# f28004x_periph_ac_regs register map
Vendor: Texas Instruments
Peripheral module from a debugger description file (folder C2000).
Address unit: 16 bits
Registers are 32-bit, read-write, no defined reset value unless marked. A register's access mark holds for its fields unless they carry their own. Offsets are as the file gives them; lines under a group give offsets from that group; [hi:lo] are bit positions; {n}, {i} and the like mark numbered series; 'fields as' and 'values as' point back to an identical list; <NAME> marks a mode.

## PERIPH_AC_REGS — PERIPH AC Registers
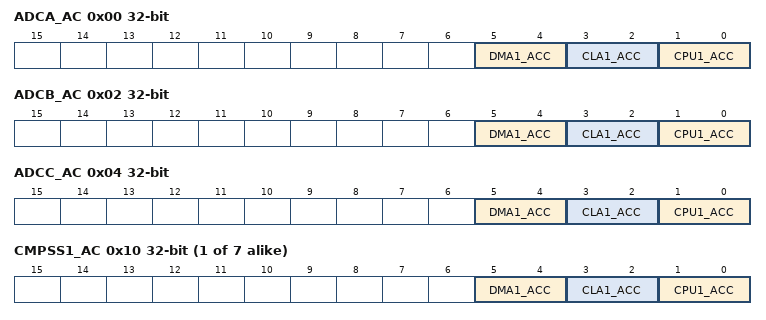
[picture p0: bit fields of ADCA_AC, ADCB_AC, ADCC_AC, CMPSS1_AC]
0x00 ADCA_AC — ADCA Master Access Control Register
  [5:4] DMA1_ACC — DMA1 Access Conditions to Peripheral
  [3:2] CLA1_ACC — CLA1 Access Conditions to Peripheral
  [1:0] CPU1_ACC — CPU1 Access conditions to peripheral
0x02 ADCB_AC — ADCB Master Access Control Register
  fields as ADCA_AC
0x04 ADCC_AC — ADCC Master Access Control Register
  fields as ADCA_AC
{0xE+2i} CMPSS{i}_AC (i=1..7) — CMPSS{i} Master Access Control Register
  fields as ADCA_AC
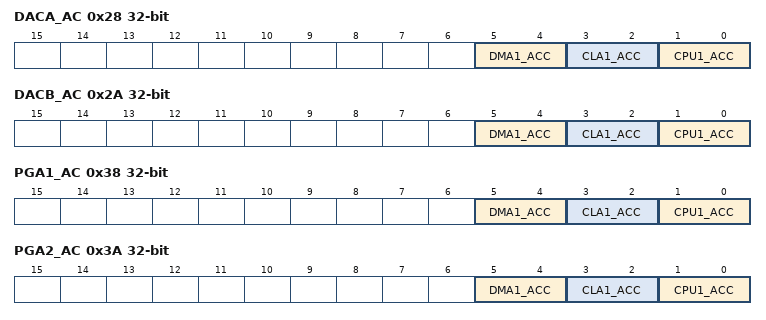
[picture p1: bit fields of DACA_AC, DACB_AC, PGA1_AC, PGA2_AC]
0x28 DACA_AC — DACA Master Access Control Register
  fields as ADCA_AC
0x2A DACB_AC — DACB Master Access Control Register
  fields as ADCA_AC
0x38 PGA1_AC — PGAA Master Access Control Register
  fields as ADCA_AC
0x3A PGA2_AC — PGAB Master Access Control Register
  fields as ADCA_AC
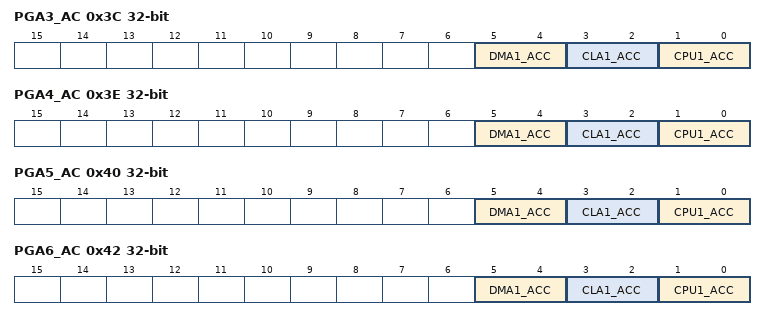
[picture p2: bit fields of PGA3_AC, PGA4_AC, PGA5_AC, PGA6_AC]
0x3C PGA3_AC — PGAC Master Access Control Register
  fields as ADCA_AC
0x3E PGA4_AC — PGAD Master Access Control Register
  fields as ADCA_AC
0x40 PGA5_AC — PGAE Master Access Control Register
  fields as ADCA_AC
0x42 PGA6_AC — PGAF Master Access Control Register
  fields as ADCA_AC
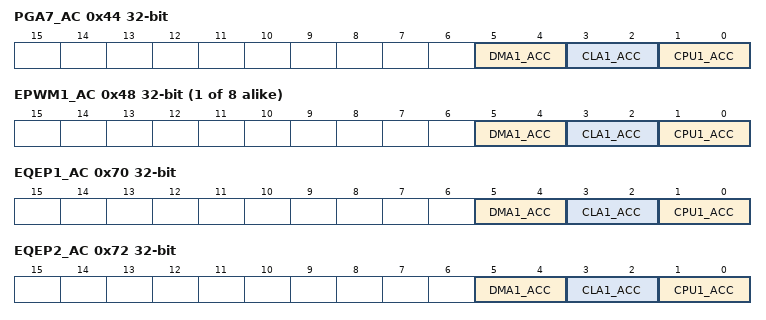
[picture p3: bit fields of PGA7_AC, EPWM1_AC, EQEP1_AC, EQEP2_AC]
0x44 PGA7_AC — PGAG Master Access Control Register
  fields as ADCA_AC
{0x46+2i} EPWM{i}_AC (i=1..8) — EPWM{i} Master Access Control Register
  fields as ADCA_AC
0x70 EQEP1_AC — EQEP1 Master Access Control Register
  fields as ADCA_AC
0x72 EQEP2_AC — EQEP2 Master Access Control Register
  fields as ADCA_AC
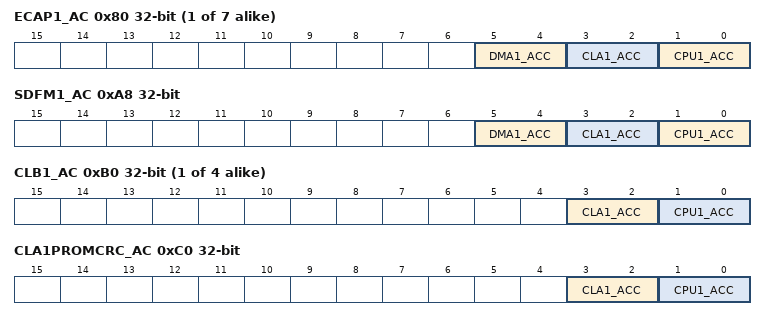
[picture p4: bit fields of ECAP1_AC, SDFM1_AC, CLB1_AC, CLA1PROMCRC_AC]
{0x7E+2i} ECAP{i}_AC (i=1..7) — ECAP{i} Master Access Control Register
  fields as ADCA_AC
0xA8 SDFM1_AC — SDFM1 Master Access Control Register
  fields as ADCA_AC
{0xAE+2i} CLB{i}_AC (i=1..4) — CLB{i} Master Access Control Register
  [3:2] CLA1_ACC — CLA1 Access Conditions to Peripheral
  [1:0] CPU1_ACC — CPU1 Access conditions to peripheral
0xC0 CLA1PROMCRC_AC — CLA1PROMCRC Master Access Control Register
  fields as CLB1_AC
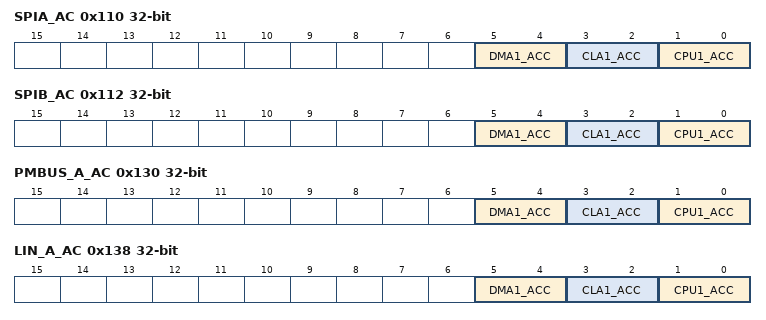
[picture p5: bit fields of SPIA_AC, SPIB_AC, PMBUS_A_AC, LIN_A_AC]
0x110 SPIA_AC — SPIA Master Access Control Register
  fields as ADCA_AC
0x112 SPIB_AC — SPIB Master Access Control Register
  fields as ADCA_AC
0x130 PMBUS_A_AC — PMBUSA Master Access Control Register
  fields as ADCA_AC
0x138 LIN_A_AC — LINA Master Access Control Register
  fields as ADCA_AC
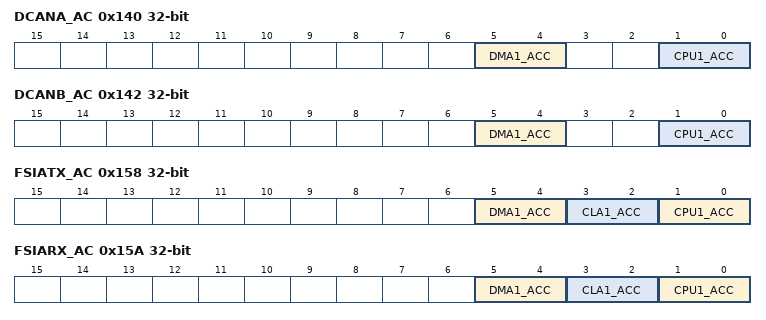
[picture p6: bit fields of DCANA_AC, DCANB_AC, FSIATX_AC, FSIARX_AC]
0x140 DCANA_AC — DCANA Master Access Control Register
  [5:4] DMA1_ACC — DMA1 Access Conditions to Peripheral
  [1:0] CPU1_ACC — CPU1 Access conditions to peripheral
0x142 DCANB_AC — DCANB Master Access Control Register
  fields as DCANA_AC
0x158 FSIATX_AC — FSIA Master Access Control Register
  fields as ADCA_AC
0x15A FSIARX_AC — FSIB Master Access Control Register
  fields as ADCA_AC
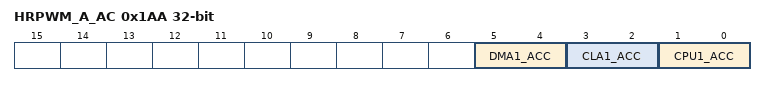
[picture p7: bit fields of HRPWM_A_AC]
0x1AA HRPWM_A_AC — HRPWM Master Access Control Register
  fields as ADCA_AC
0x1FE PERIPH_AC_LOCK access not given — Lock Register to stop Write access to peripheral Access register.
  [0] LOCK_AC_WR — Lock control for Access control registers write. (access R/SOnce)
